# UPD70F3508 register map
Vendor: Renesas; Series: V850E2/Px4; File version: 1.0
CPU: other r0p0, little endian, no MPU, FPU, 4 interrupt priority bits
Registers are 8-bit, read-write, reset 0x0 unless marked. A register's access mark holds for its fields unless they carry their own. Offsets are from the block's base; [hi:lo] are bit positions; {n}, {i} and the like mark numbered series.

## DTSFSL — DTS Factor Selector — DTSENn transfer enable registers (n=0..111) and DTSHENm hold enable registers (m=0..3)
Base 0xFFFF7D00
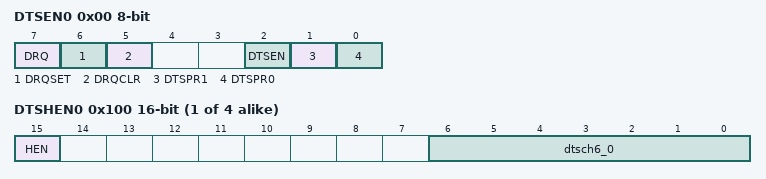
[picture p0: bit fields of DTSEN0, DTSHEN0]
0x00 DTSEN0 — DTS Transfer Enable Register channel 0
  [7] DRQ — DTS transfer request pending (read-only)
  [6] DRQSET — Write 1 to set DRQ bit
  [5] DRQCLR — Write 1 to clear DRQ bit
  [2] DTSEN — DTS transfer request enable for this channel
  [1] DTSPR1 — Priority level bit 1
  [0] DTSPR0 — Priority level bit 0
{0x0+2i} DTSEN{i} (i=1..111) — DTS Transfer Enable Register channel {i}
{0x100+2i} DTSHEN{i} 16-bit (i=0..3) — DTS Hold Enable Register {i}
  [15] HEN — Hold-enable register operation enable
  [6:0] dtsch6_0 — Target channel for holding [6:0]

## PORT_DATA — Port 0 data and mode control registers (merged: PORT0_DATA, PORT1_DATA, PORT2_DATA, PORT3_DATA, PORT4_DATA, PORT5_DATA, PORT6_DATA, PORT7_DATA, PORT8_DATA)
Base 0xFFFF8000
0x00 P0 16-bit — Port 0 register
  [15:0] P0_15_0 — Port 0 output data bits [15:0]
{0x0+4i} P{i} 16-bit (i=1..7) — Port {i} register
0x20 P8 16-bit — Port 8 register (only bit 0 / P8_0 is implemented)
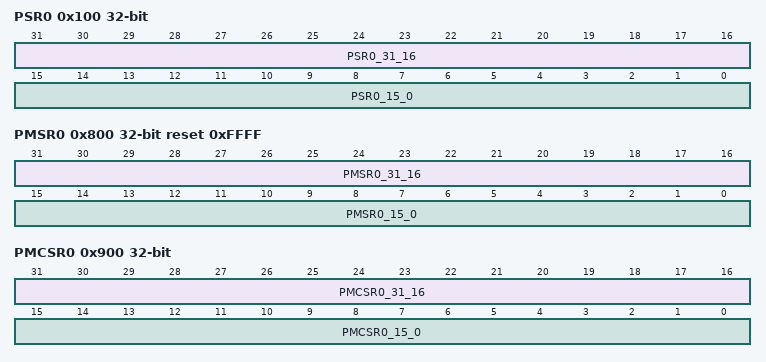
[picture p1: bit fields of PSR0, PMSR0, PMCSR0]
0x100 PSR0 32-bit — Port 0 set reset register
  [31:16] PSR0_31_16 — Mask bits: 1 = corresponding lower bit is written to P0
  [15:0] PSR0_15_0 — Value bits for P0 when corresponding mask bit is 1
{0x100+4i} PSR{i} 32-bit (i=1..8) — Port {i} set reset register
0x200 PPR0 16-bit ro — Port 0 pin read register
  [15:0] PPR0_15_0 — Pin P0_m, P0.P0_m value, or alternative function output
{0x200+4i} PPR{i} 16-bit ro (i=1..8) — Port {i} pin read register
0x300 PM0 16-bit reset 0xFFFF — Port 0 mode register (0=output, 1=input)
  [15:0] PM0_15_0 — I/O mode bits: 0=output, 1=input
0x304 PM1 16-bit reset 0xFFFF — Port 1 mode register (0=output, 1=input)
{0x300+4i} PM{i} 16-bit reset 0xFFFF (i=2..8) — Port {i} mode register
0x400 PMC0 16-bit — Port 0 mode control register (0=port mode, 1=alternative mode)
  [15:0] PMC0_15_0 — Pin mode: 0=port mode, 1=alternative mode
{0x400+4i} PMC{i} 16-bit (i=1..7) — Port {i} mode control register
0x500 PFC0 16-bit — Port 0 function control register
  [15:0] PFC0_15_0 — Alternative function select (with PFCE0)
{0x500+4i} PFC{i} 16-bit (i=1..7) — Port {i} function control register
0x600 PFCE0 16-bit — Port 0 function control expansion register
  [15:0] PFCE0_15_0 — Alternative function expansion select (with PFC0)
{0x600+4i} PFCE{i} 16-bit (i=1..7) — Port {i} function control expansion register
0x700 PNOT0 16-bit wo — Port 0 NOT register (write 1 to invert corresponding P0 bit)
  [15:0] PNOT0_15_0 — Write 1 to invert P0.P0_m
{0x700+4i} PNOT{i} 16-bit wo (i=1..8) — Port {i} NOT register
0x800 PMSR0 32-bit reset 0xFFFF — Port 0 mode set reset register
  [31:16] PMSR0_31_16 — Mask bits: 1 = corresponding lower PM0 bit is written
  [15:0] PMSR0_15_0 — Value bits for PM0 when corresponding mask bit is 1
{0x800+4i} PMSR{i} 32-bit reset 0xFFFF (i=1..8) — Port {i} mode set reset register
0x900 PMCSR0 32-bit — Port 0 mode control set reset register
  [31:16] PMCSR0_31_16 — Mask bits: 1 = corresponding PMC0 bit is written
  [15:0] PMCSR0_15_0 — Value bits for PMC0 when corresponding mask bit is 1
{0x900+4i} PMCSR{i} 32-bit (i=1..7) — Port {i} mode control set reset register

## TAUJ0 — Timer Array Unit J 0 - Channel Registers (base1)
Base 0xFFFFC200
{0x0+4i} TAUJ0CDR{i} 32-bit (i=0..3) — TAUJn Channel Data Register {i} (compare/capture)
  [31:0] CDR — 32-bit data register (compare or capture value)
{0x10+4i} TAUJ0CNT{i} 32-bit ro (i=0..3) — TAUJn Channel Counter Register {i}
  [31:0] CNT — 32-bit counter value
{0x20+4i} TAUJ0CMUR{i} (i=0..3) — TAUJn Channel Mode User Register {i}
  [1:0] TIS — Valid edge select for TAUJnTTINm [1:0]
{0x30+4i} TAUJ0CSR{i} ro (i=0..3) — TAUJn Channel Status Register {i}
  [0] OVF — Counter overflow flag (capture modes only)
{0x40+4i} TAUJ0CSC{i} wo (i=0..3) — TAUJn Channel Status Clear Trigger Register {i}
  [0] CLOV — Clear overflow flag TAUJnCSRm.OVF
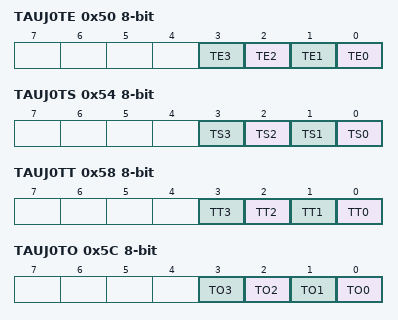
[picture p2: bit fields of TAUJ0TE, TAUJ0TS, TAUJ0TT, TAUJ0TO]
0x50 TAUJ0TE ro — TAUJn Channel Enable Status Register
  [n] TE{n} (n=0..3) — Channel {n} counter enable status
0x54 TAUJ0TS wo — TAUJn Channel Start Trigger Register
  [n] TS{n} (n=0..3) — Enable counter operation for channel {n}
0x58 TAUJ0TT wo — TAUJn Channel Stop Trigger Register
  [n] TT{n} (n=0..3) — Stop counter operation for channel {n}
0x5C TAUJ0TO — TAUJn Channel Output Register
  [n] TO{n} (n=0..3) — Channel {n} TTOUTm level (0=low, 1=high)
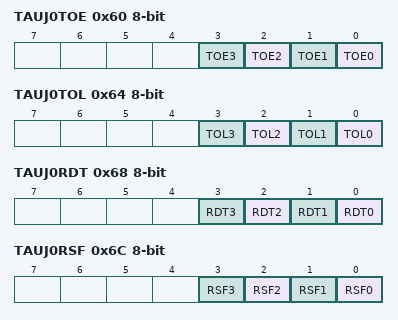
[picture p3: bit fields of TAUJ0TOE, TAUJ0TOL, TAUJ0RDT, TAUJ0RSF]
0x60 TAUJ0TOE — TAUJn Channel Output Enable Register
  [n] TOE{n} (n=0..3) — Channel {n} independent timer output enable
0x64 TAUJ0TOL — TAUJn Channel Output Active Level Register
  [n] TOL{n} (n=0..3) — Channel {n} output logic (0=active high, 1=active low)
0x68 TAUJ0RDT wo — TAUJn Channel Reload Data Trigger Register
  [n] RDT{n} (n=0..3) — Trigger simultaneous rewrite pending for channel {n}
0x6C TAUJ0RSF ro — TAUJn Channel Reload Status Register
  [n] RSF{n} (n=0..3) — Channel {n} simultaneous rewrite pending status

## TAUJ1 — Timer Array Unit J 1 - Channel Registers (base1)
Base 0xFFFFC300
Registers as TAUJ0 (with TAUJ0 read as TAUJ1).
